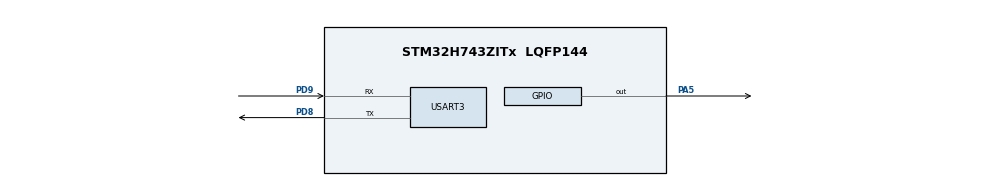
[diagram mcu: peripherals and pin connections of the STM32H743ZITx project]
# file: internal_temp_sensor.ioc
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ADC3.Channel-0\#ChannelRegularConversion=ADC_CHANNEL_TEMPSENSOR
ADC3.NbrOfConversionFlag=1
ADC3.OffsetNumber-0\#ChannelRegularConversion=ADC_OFFSET_NONE
ADC3.Rank-0\#ChannelRegularConversion=1
ADC3.SamplingTime-0\#ChannelRegularConversion=ADC_SAMPLETIME_1CYCLE_5
Mcu.Family=STM32H7
Mcu.Name=STM32H743ZITx
Mcu.Package=LQFP144
NVIC.PriorityGroup=NVIC_PRIORITYGROUP_4
PA5.Signal=GPIO_Output
PD8.Mode=Asynchronous
PD8.Signal=USART3_TX
PD9.Mode=Asynchronous
PD9.Signal=USART3_RX
ProjectManager.HeapSize=0x200
ProjectManager.StackSize=0x400
ProjectManager.TargetToolchain=SW4STM32
RCC.ADCCLockSelection=RCC_ADCCLKSOURCE_PLL3
RCC.ADCFreq_Value=17200000
RCC.APB1Freq_Value=64000000
RCC.APB2Freq_Value=64000000
RCC.APB3Freq_Value=64000000
RCC.APB4Freq_Value=64000000
RCC.CortexFreq_Value=64000000
RCC.DIVR3=15
RCC.HCLKFreq_Value=64000000
RCC.SYSCLKFreq_VALUE=64000000
RCC.USBFreq_Value=129000000
USART3.VirtualMode-Asynchronous=VM_ASYNC
VP_ADC3_TempSens_Input.Mode=IN-TempSens
board=custom

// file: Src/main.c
/**
  ******************************************************************************
  * @file           : main.c
  * @brief          : Main program body
  ******************************************************************************
  ** This notice applies to any and all portions of this file
  * that are not between comment pairs USER CODE BEGIN and
  * USER CODE END. Other portions of this file, whether
  * inserted by the user or by software development tools
  * are owned by their respective copyright owners.
  *
  * COPYRIGHT(c) 2018 STMicroelectronics
  *
  * Redistribution and use in source and binary forms, with or without modification,
  * are permitted provided that the following conditions are met:
  *   1. Redistributions of source code must retain the above copyright notice,
  *      this list of conditions and the following disclaimer.
  *   2. Redistributions in binary form must reproduce the above copyright notice,
  *      this list of conditions and the following disclaimer in the documentation
  *      and/or other materials provided with the distribution.
  *   3. Neither the name of STMicroelectronics nor the names of its contributors
  *      may be used to endorse or promote products derived from this software
  *      without specific prior written permission.
  *
  * THIS SOFTWARE IS PROVIDED BY THE COPYRIGHT HOLDERS AND CONTRIBUTORS "AS IS"
  * AND ANY EXPRESS OR IMPLIED WARRANTIES, INCLUDING, BUT NOT LIMITED TO, THE
  * IMPLIED WARRANTIES OF MERCHANTABILITY AND FITNESS FOR A PARTICULAR PURPOSE ARE
  * DISCLAIMED. IN NO EVENT SHALL THE COPYRIGHT HOLDER OR CONTRIBUTORS BE LIABLE
  * FOR ANY DIRECT, INDIRECT, INCIDENTAL, SPECIAL, EXEMPLARY, OR CONSEQUENTIAL
  * DAMAGES (INCLUDING, BUT NOT LIMITED TO, PROCUREMENT OF SUBSTITUTE GOODS OR
  * SERVICES; LOSS OF USE, DATA, OR PROFITS; OR BUSINESS INTERRUPTION) HOWEVER
  * CAUSED AND ON ANY THEORY OF LIABILITY, WHETHER IN CONTRACT, STRICT LIABILITY,
  * OR TORT (INCLUDING NEGLIGENCE OR OTHERWISE) ARISING IN ANY WAY OUT OF THE USE
  * OF THIS SOFTWARE, EVEN IF ADVISED OF THE POSSIBILITY OF SUCH DAMAGE.
  *
  ******************************************************************************
  */
#include "main.h"
#include "stm32h7xx_hal.h"
#include <string.h>

ADC_HandleTypeDef hadc3;

UART_HandleTypeDef huart3;

/* USER CODE BEGIN PV */
/* Private variables ---------------------------------------------------------*/

/* USER CODE END PV */

void SystemClock_Config(void);
static void MX_GPIO_Init(void);
static void MX_ADC3_Init(void);
static void MX_USART3_UART_Init(void);

/* USER CODE BEGIN PFP */
/* Private function prototypes -----------------------------------------------*/
void double_to_string (double val, char *msg);
/* USER CODE END PFP */

int main(void)
{

  /* MCU Configuration----------------------------------------------------------*/

  /* Reset of all peripherals, Initializes the Flash interface and the Systick. */
  HAL_Init();

  /* Configure the system clock */
  SystemClock_Config();

  /* Initialize all configured peripherals */
  MX_GPIO_Init();
  MX_ADC3_Init();
  MX_USART3_UART_Init();
  /* USER CODE BEGIN 2 */

  /* Get temperature calibration values */
  const uint32_t *TS_CAL1 = (const uint32_t*) 0x1FF1E820;
  const uint32_t *TS_CAL2 = (const uint32_t*) 0x1FF1E840;

  /* Run ADC calibration in single-ended mode */
  HAL_ADCEx_Calibration_Start(&hadc3, ADC_CALIB_OFFSET, ADC_SINGLE_ENDED);

  /* USER CODE END 2 */

  /* Infinite loop */
  /* USER CODE BEGIN WHILE */
  while (1)
  {
	  uint32_t adc_value;
	  double temp_in_C;
	  char msg[5];
	  char *to_print = "Temperature is: ";

	  /* Start the ADC Conversion */
	  HAL_ADC_Start(&hadc3);

	  /* Wait for conversion to be done */
	  while (HAL_ADC_PollForConversion(&hadc3, 10) != HAL_OK);

	  /* Convert value to Celsius */
	  adc_value = HAL_ADC_GetValue(&hadc3);
	  temp_in_C = (double)(110-30)/(*TS_CAL2 - *TS_CAL1)*((int32_t)adc_value - (int32_t)*TS_CAL1) + 30;

	  /* Stop the Conversion */
	  HAL_ADC_Stop(&hadc3);

	  /* Print */
	  double_to_string(temp_in_C, msg);

	  HAL_UART_Transmit(&huart3, (uint8_t *)to_print, strlen(to_print), 0xFF);
	  HAL_UART_Transmit(&huart3, (uint8_t *)msg, 5, 0xFF);

	  HAL_Delay(2000);
  /* USER CODE END WHILE */

  }

}

void SystemClock_Config(void)
{

  RCC_OscInitTypeDef RCC_OscInitStruct;
  RCC_ClkInitTypeDef RCC_ClkInitStruct;
  RCC_PeriphCLKInitTypeDef PeriphClkInitStruct;

    /**Supply configuration update enable
    */
  MODIFY_REG(PWR->CR3, PWR_CR3_SCUEN, 0);

    /**Configure the main internal regulator output voltage
    */
  __HAL_PWR_VOLTAGESCALING_CONFIG(PWR_REGULATOR_VOLTAGE_SCALE3);

  while ((PWR->D3CR & (PWR_D3CR_VOSRDY)) != PWR_D3CR_VOSRDY)
  {

  }
    /**Macro to configure the PLL clock source
    */
  __HAL_RCC_PLL_PLLSOURCE_CONFIG(RCC_PLLSOURCE_HSI);

    /**Initializes the CPU, AHB and APB busses clocks
    */
  RCC_OscInitStruct.OscillatorType = RCC_OSCILLATORTYPE_HSI;
  RCC_OscInitStruct.HSIState = RCC_HSI_DIV1;
  RCC_OscInitStruct.HSICalibrationValue = 16;
  RCC_OscInitStruct.PLL.PLLState = RCC_PLL_NONE;
  RCC_OscInitStruct.PLL.PLLSource = RCC_PLLSOURCE_HSI;
  if (HAL_RCC_OscConfig(&RCC_OscInitStruct) != HAL_OK)
  {
    _Error_Handler(__FILE__, __LINE__);
  }

    /**Initializes the CPU, AHB and APB busses clocks
    */
  RCC_ClkInitStruct.ClockType = RCC_CLOCKTYPE_HCLK|RCC_CLOCKTYPE_SYSCLK
                              |RCC_CLOCKTYPE_PCLK1|RCC_CLOCKTYPE_PCLK2
                              |RCC_CLOCKTYPE_D3PCLK1|RCC_CLOCKTYPE_D1PCLK1;
  RCC_ClkInitStruct.SYSCLKSource = RCC_SYSCLKSOURCE_HSI;
  RCC_ClkInitStruct.SYSCLKDivider = RCC_SYSCLK_DIV1;
  RCC_ClkInitStruct.AHBCLKDivider = RCC_HCLK_DIV1;
  RCC_ClkInitStruct.APB3CLKDivider = RCC_APB3_DIV1;
  RCC_ClkInitStruct.APB1CLKDivider = RCC_APB1_DIV1;
  RCC_ClkInitStruct.APB2CLKDivider = RCC_APB2_DIV1;
  RCC_ClkInitStruct.APB4CLKDivider = RCC_APB4_DIV1;

  if (HAL_RCC_ClockConfig(&RCC_ClkInitStruct, FLASH_LATENCY_0) != HAL_OK)
  {
    _Error_Handler(__FILE__, __LINE__);
  }

  PeriphClkInitStruct.PeriphClockSelection = RCC_PERIPHCLK_USART3|RCC_PERIPHCLK_ADC;
  PeriphClkInitStruct.PLL3.PLL3M = 32;
  PeriphClkInitStruct.PLL3.PLL3N = 129;
  PeriphClkInitStruct.PLL3.PLL3P = 2;
  PeriphClkInitStruct.PLL3.PLL3Q = 2;
  PeriphClkInitStruct.PLL3.PLL3R = 15;
  PeriphClkInitStruct.PLL3.PLL3RGE = RCC_PLL3VCIRANGE_1;
  PeriphClkInitStruct.PLL3.PLL3VCOSEL = RCC_PLL3VCOWIDE;
  PeriphClkInitStruct.PLL3.PLL3FRACN = 0;
  PeriphClkInitStruct.Usart234578ClockSelection = RCC_USART234578CLKSOURCE_D2PCLK1;
  PeriphClkInitStruct.AdcClockSelection = RCC_ADCCLKSOURCE_PLL3;
  if (HAL_RCCEx_PeriphCLKConfig(&PeriphClkInitStruct) != HAL_OK)
  {
    _Error_Handler(__FILE__, __LINE__);
  }

    /**Configure the Systick interrupt time
    */
  HAL_SYSTICK_Config(SystemCoreClock/1000);

    /**Configure the Systick
    */
  HAL_SYSTICK_CLKSourceConfig(SYSTICK_CLKSOURCE_HCLK);

  /* SysTick_IRQn interrupt configuration */
  HAL_NVIC_SetPriority(SysTick_IRQn, 0, 0);
}

/* ADC3 init function */
static void MX_ADC3_Init(void)
{

  ADC_ChannelConfTypeDef sConfig;

    /**Common config
    */
  hadc3.Instance = ADC3;
  hadc3.Init.ClockPrescaler = ADC_CLOCK_ASYNC_DIV1;
  hadc3.Init.Resolution = ADC_RESOLUTION_16B;
  hadc3.Init.ScanConvMode = ADC_SCAN_DISABLE;
  hadc3.Init.EOCSelection = ADC_EOC_SINGLE_CONV;
  hadc3.Init.LowPowerAutoWait = DISABLE;
  hadc3.Init.ContinuousConvMode = DISABLE;
  hadc3.Init.NbrOfConversion = 1;
  hadc3.Init.DiscontinuousConvMode = DISABLE;
  hadc3.Init.NbrOfDiscConversion = 1;
  hadc3.Init.ExternalTrigConv = ADC_SOFTWARE_START;
  hadc3.Init.ExternalTrigConvEdge = ADC_EXTERNALTRIGCONVEDGE_NONE;
  hadc3.Init.ConversionDataManagement = ADC_CONVERSIONDATA_DR;
  hadc3.Init.Overrun = ADC_OVR_DATA_PRESERVED;
  hadc3.Init.LeftBitShift = ADC_LEFTBITSHIFT_NONE;
  hadc3.Init.BoostMode = DISABLE;
  hadc3.Init.OversamplingMode = DISABLE;
  if (HAL_ADC_Init(&hadc3) != HAL_OK)
  {
    _Error_Handler(__FILE__, __LINE__);
  }

    /**Configure Regular Channel
    */
  sConfig.Channel = ADC_CHANNEL_TEMPSENSOR;
  sConfig.Rank = ADC_REGULAR_RANK_1;
  sConfig.SamplingTime = ADC_SAMPLETIME_387CYCLES_5;
  sConfig.SingleDiff = ADC_SINGLE_ENDED;
  sConfig.OffsetNumber = ADC_OFFSET_NONE;
  sConfig.Offset = 0;
  if (HAL_ADC_ConfigChannel(&hadc3, &sConfig) != HAL_OK)
  {
    _Error_Handler(__FILE__, __LINE__);
  }

}

/* USART3 init function */
static void MX_USART3_UART_Init(void)
{

  huart3.Instance = USART3;
  huart3.Init.BaudRate = 115200;
  huart3.Init.WordLength = UART_WORDLENGTH_8B;
  huart3.Init.StopBits = UART_STOPBITS_1;
  huart3.Init.Parity = UART_PARITY_NONE;
  huart3.Init.Mode = UART_MODE_TX_RX;
  huart3.Init.HwFlowCtl = UART_HWCONTROL_NONE;
  huart3.Init.OverSampling = UART_OVERSAMPLING_16;
  huart3.Init.OneBitSampling = UART_ONE_BIT_SAMPLE_DISABLE;
  huart3.Init.Prescaler = UART_PRESCALER_DIV1;
  huart3.Init.FIFOMode = UART_FIFOMODE_DISABLE;
  huart3.Init.TXFIFOThreshold = UART_TXFIFO_THRESHOLD_1_8;
  huart3.Init.RXFIFOThreshold = UART_RXFIFO_THRESHOLD_1_8;
  huart3.AdvancedInit.AdvFeatureInit = UART_ADVFEATURE_NO_INIT;
  if (HAL_UART_Init(&huart3) != HAL_OK)
  {
    _Error_Handler(__FILE__, __LINE__);
  }

}

/** Configure pins as
        * Analog
        * Input
        * Output
        * EVENT_OUT
        * EXTI
*/
static void MX_GPIO_Init(void)
{

  GPIO_InitTypeDef GPIO_InitStruct;

  /* GPIO Ports Clock Enable */
  __HAL_RCC_GPIOA_CLK_ENABLE();
  __HAL_RCC_GPIOD_CLK_ENABLE();

  /*Configure GPIO pin Output Level */
  HAL_GPIO_WritePin(GPIOA, GPIO_PIN_5, GPIO_PIN_RESET);

  /*Configure GPIO pin : PA5 */
  GPIO_InitStruct.Pin = GPIO_PIN_5;
  GPIO_InitStruct.Mode = GPIO_MODE_OUTPUT_PP;
  GPIO_InitStruct.Pull = GPIO_NOPULL;
  GPIO_InitStruct.Speed = GPIO_SPEED_FREQ_LOW;
  HAL_GPIO_Init(GPIOA, &GPIO_InitStruct);

}

/* USER CODE BEGIN 4 */
/* Hard-coded way of converting one decimal value to string */
void double_to_string (double val, char msg[]) {
	int temp_val = (int)(val*10);
	msg[0] = (temp_val/100)%10 + '0';
	msg[1] = (temp_val/10)%10 + '0';
	msg[2] = '.';
	msg[3] = temp_val%10 + '0';
	msg[4] = '\n';
}
/* USER CODE END 4 */

void _Error_Handler(char *file, int line)
{
  while(1)
  {
  }
}

/************************ (C) COPYRIGHT STMicroelectronics *****END OF FILE****/
